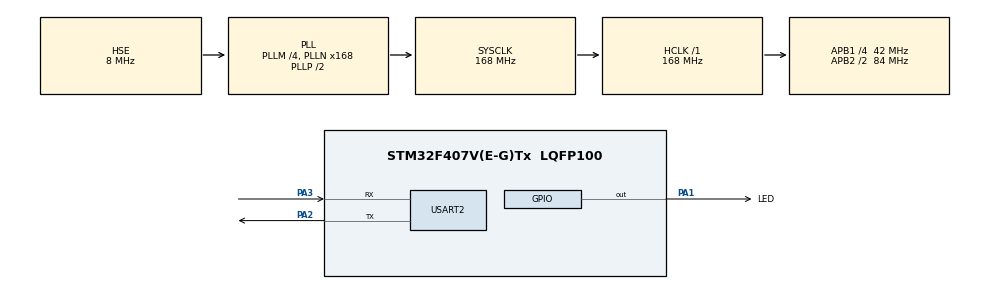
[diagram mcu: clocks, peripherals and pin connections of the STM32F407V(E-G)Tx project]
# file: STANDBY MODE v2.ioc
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Mcu.Family=STM32F4
Mcu.Name=STM32F407V(E-G)Tx
Mcu.Package=LQFP100
NVIC.PriorityGroup=NVIC_PRIORITYGROUP_4
NVIC.RTC_WKUP_IRQn=true\:0\:0\:false\:false\:true\:true\:true
PA0-WKUP.Mode=SYS_WakeUp0
PA0-WKUP.Signal=SYS_WKUP
PA1.GPIO_Label=LED
PA1.Signal=GPIO_Output
PA13.Mode=Serial_Wire
PA13.Signal=SYS_JTMS-SWDIO
PA14.Mode=Serial_Wire
PA14.Signal=SYS_JTCK-SWCLK
PA2.Mode=Asynchronous
PA2.Signal=USART2_TX
PA3.Mode=Asynchronous
PA3.Signal=USART2_RX
PH0-OSC_IN.Mode=HSE-External-Oscillator
PH0-OSC_IN.Signal=RCC_OSC_IN
PH1-OSC_OUT.Mode=HSE-External-Oscillator
PH1-OSC_OUT.Signal=RCC_OSC_OUT
ProjectManager.HeapSize=0x200
ProjectManager.StackSize=0x400
ProjectManager.TargetToolchain=STM32CubeIDE
RCC.48MHZClocksFreq_Value=84000000
RCC.AHBFreq_Value=168000000
RCC.APB1CLKDivider=RCC_HCLK_DIV4
RCC.APB1Freq_Value=42000000
RCC.APB1TimFreq_Value=84000000
RCC.APB2CLKDivider=RCC_HCLK_DIV2
RCC.APB2Freq_Value=84000000
RCC.APB2TimFreq_Value=168000000
RCC.CortexFreq_Value=168000000
RCC.HCLKFreq_Value=168000000
RCC.HSE_VALUE=8000000
RCC.HSI_VALUE=16000000
RCC.LSE_VALUE=32768
RCC.PLLM=4
RCC.PLLN=168
RCC.PLLSourceVirtual=RCC_PLLSOURCE_HSE
RCC.SYSCLKFreq_VALUE=168000000
RCC.SYSCLKSource=RCC_SYSCLKSOURCE_PLLCLK
RCC.VCOOutputFreq_Value=336000000
USART2.VirtualMode=VM_ASYNC
VP_RTC_VS_RTC_Activate.Mode=RTC_Enabled
VP_RTC_VS_RTC_WakeUp_intern.Mode=WakeUp
board=custom

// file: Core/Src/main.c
/* USER CODE BEGIN Header */
/**
  ******************************************************************************
  * @file           : main.c
  * @brief          : Main program body
  ******************************************************************************
  * @attention
  *
  * <h2><center>&copy; Copyright (c) 2021 STMicroelectronics.
  * All rights reserved.</center></h2>
  *
  * This software component is licensed by ST under BSD 3-Clause license,
  * the "License"; You may not use this file except in compliance with the
  * License. You may obtain a copy of the License at:
  *                        opensource.org/licenses/BSD-3-Clause
  *
  ******************************************************************************
  */
/* USER CODE END Header */
#include "main.h"

/* USER CODE BEGIN Includes */
#include "string.h"
/* USER CODE END Includes */

RTC_HandleTypeDef hrtc;

UART_HandleTypeDef huart2;

void SystemClock_Config(void);
static void MX_GPIO_Init(void);
static void MX_RTC_Init(void);
static void MX_USART2_UART_Init(void);

int main(void)
{

  /* MCU Configuration--------------------------------------------------------*/

  /* Reset of all peripherals, Initializes the Flash interface and the Systick. */
  HAL_Init();

  /* Configure the system clock */
  SystemClock_Config();

  /* Initialize all configured peripherals */
  MX_GPIO_Init();
  MX_RTC_Init();
  MX_USART2_UART_Init();
  /* USER CODE BEGIN 2 */

  /*** Check if the SB flag is set это означает, что MCU вышел из STANDBY MODE!***/
   if (__HAL_PWR_GET_FLAG(PWR_FLAG_SB) != RESET)
   {
 	  __HAL_PWR_CLEAR_FLAG(PWR_FLAG_SB);  // clear the flag

 	  /** display  the string **/
 	  char *str = "Wakeup from the STANDBY MODE\n\n";
 	  HAL_UART_Transmit(&huart2, (uint8_t *)str, strlen (str), HAL_MAX_DELAY);

 	  /** Blink the LED **/
 	  for (int i=0; i<20; i++)
 	  {
 		  HAL_GPIO_TogglePin(LED_GPIO_Port, LED_Pin);
 		  HAL_Delay(200);
 	  }

 	  /** Disable the WWAKEUP PIN **/
 	  HAL_PWR_DisableWakeUpPin(PWR_WAKEUP_PIN1);  // disable PA0

 	  /** Deactivate the RTC wakeup  **/
 	  HAL_RTCEx_DeactivateWakeUpTimer(&hrtc);
   }

   /** Now enter the standby mode **/
    /* Clear the WU FLAG */
   __HAL_PWR_CLEAR_FLAG(PWR_FLAG_WU);

    /* clear the RTC Wake UP (WU) flag */
   __HAL_RTC_WAKEUPTIMER_CLEAR_FLAG(&hrtc, RTC_FLAG_WUTF);

    /* Display the string */
   char *str = "About to enter the STANDBY MODE\n\n";
   HAL_UART_Transmit(&huart2, (uint8_t *)str, strlen (str), HAL_MAX_DELAY);

    /* Blink the LED */
   for (int i=0; i<5; i++)
   {
 	  HAL_GPIO_TogglePin(LED_GPIO_Port, LED_Pin);
 	  HAL_Delay(750);
   }

    /* Enable the WAKEUP PIN */
   HAL_PWR_EnableWakeUpPin(PWR_WAKEUP_PIN1); //Enable PA0

   /* enable the RTC Wakeup */
     /*  RTC Wake-up Interrupt Generation:
       Wake-up Time Base = (RTC_WAKEUPCLOCK_RTCCLK_DIV /(LSI))
       ==> WakeUpCounter = Wake-up Time / Wake-up Time Base

       To configure the wake up timer to 5s the WakeUpCounter is set to 0x2710:
       RTC_WAKEUPCLOCK_RTCCLK_DIV = RTCCLK_Div16 = 16
       Wake-up Time Base = 16 /(32KHz) = 0.0005 seconds
       ==> WakeUpCounter = ~5s/0.0005s = 10000 = 0x2710
       ==> WakeUpCounter = ~10s/0.0005s = 20000 = 0x4E20
       ==> WakeUpCounter = ~15s/0.0005s = 30000 = 0x7530
       ==> WakeUpCounter = ~60s/0.0005s = 120000 = 0x1D4C0
     */
   if (HAL_RTCEx_SetWakeUpTimer_IT(&hrtc, 0x1D4C0, RTC_WAKEUPCLOCK_RTCCLK_DIV16) != HAL_OK)
   {
     Error_Handler();
   }

    /* one last string to be sure */
   char *str2 = "STANDBY MODE is ON \n\n";
   HAL_UART_Transmit(&huart2, (uint8_t *)str2, strlen (str2), HAL_MAX_DELAY);

    /* Finally enter the standby mode */
   HAL_PWR_EnterSTANDBYMode();

  /* USER CODE END 2 */

  /* Infinite loop */
  while (1)
  {

  }
}

void SystemClock_Config(void)
{
  RCC_OscInitTypeDef RCC_OscInitStruct = {0};
  RCC_ClkInitTypeDef RCC_ClkInitStruct = {0};

  /** Configure the main internal regulator output voltage
  */
  __HAL_RCC_PWR_CLK_ENABLE();
  __HAL_PWR_VOLTAGESCALING_CONFIG(PWR_REGULATOR_VOLTAGE_SCALE1);
  /** Initializes the RCC Oscillators according to the specified parameters
  * in the RCC_OscInitTypeDef structure.
  */
  RCC_OscInitStruct.OscillatorType = RCC_OSCILLATORTYPE_LSI|RCC_OSCILLATORTYPE_HSE;
  RCC_OscInitStruct.HSEState = RCC_HSE_ON;
  RCC_OscInitStruct.LSIState = RCC_LSI_ON;
  RCC_OscInitStruct.PLL.PLLState = RCC_PLL_ON;
  RCC_OscInitStruct.PLL.PLLSource = RCC_PLLSOURCE_HSE;
  RCC_OscInitStruct.PLL.PLLM = 4;
  RCC_OscInitStruct.PLL.PLLN = 168;
  RCC_OscInitStruct.PLL.PLLP = RCC_PLLP_DIV2;
  RCC_OscInitStruct.PLL.PLLQ = 4;
  if (HAL_RCC_OscConfig(&RCC_OscInitStruct) != HAL_OK)
  {
    Error_Handler();
  }
  /** Initializes the CPU, AHB and APB buses clocks
  */
  RCC_ClkInitStruct.ClockType = RCC_CLOCKTYPE_HCLK|RCC_CLOCKTYPE_SYSCLK
                              |RCC_CLOCKTYPE_PCLK1|RCC_CLOCKTYPE_PCLK2;
  RCC_ClkInitStruct.SYSCLKSource = RCC_SYSCLKSOURCE_PLLCLK;
  RCC_ClkInitStruct.AHBCLKDivider = RCC_SYSCLK_DIV1;
  RCC_ClkInitStruct.APB1CLKDivider = RCC_HCLK_DIV4;
  RCC_ClkInitStruct.APB2CLKDivider = RCC_HCLK_DIV2;

  if (HAL_RCC_ClockConfig(&RCC_ClkInitStruct, FLASH_LATENCY_5) != HAL_OK)
  {
    Error_Handler();
  }
}

static void MX_RTC_Init(void)
{

  RTC_TimeTypeDef sTime = {0};
  RTC_DateTypeDef sDate = {0};

  /** Initialize RTC Only
  */
  hrtc.Instance = RTC;
  hrtc.Init.HourFormat = RTC_HOURFORMAT_24;
  hrtc.Init.AsynchPrediv = 127;
  hrtc.Init.SynchPrediv = 255;
  hrtc.Init.OutPut = RTC_OUTPUT_DISABLE;
  hrtc.Init.OutPutPolarity = RTC_OUTPUT_POLARITY_HIGH;
  hrtc.Init.OutPutType = RTC_OUTPUT_TYPE_OPENDRAIN;
  if (HAL_RTC_Init(&hrtc) != HAL_OK)
  {
    Error_Handler();
  }

  /** Initialize RTC and set the Time and Date
  */
  sTime.Hours = 0x0;
  sTime.Minutes = 0x0;
  sTime.Seconds = 0x0;
  sTime.DayLightSaving = RTC_DAYLIGHTSAVING_NONE;
  sTime.StoreOperation = RTC_STOREOPERATION_RESET;
  if (HAL_RTC_SetTime(&hrtc, &sTime, RTC_FORMAT_BCD) != HAL_OK)
  {
    Error_Handler();
  }
  sDate.WeekDay = RTC_WEEKDAY_MONDAY;
  sDate.Month = RTC_MONTH_JANUARY;
  sDate.Date = 0x1;
  sDate.Year = 0x0;

  if (HAL_RTC_SetDate(&hrtc, &sDate, RTC_FORMAT_BCD) != HAL_OK)
  {
    Error_Handler();
  }
  /** Enable the WakeUp
  */
 /* if (HAL_RTCEx_SetWakeUpTimer_IT(&hrtc, 0, RTC_WAKEUPCLOCK_RTCCLK_DIV16) != HAL_OK)
  {
    Error_Handler();
  }*/

}

static void MX_USART2_UART_Init(void)
{

  huart2.Instance = USART2;
  huart2.Init.BaudRate = 115200;
  huart2.Init.WordLength = UART_WORDLENGTH_8B;
  huart2.Init.StopBits = UART_STOPBITS_1;
  huart2.Init.Parity = UART_PARITY_NONE;
  huart2.Init.Mode = UART_MODE_TX_RX;
  huart2.Init.HwFlowCtl = UART_HWCONTROL_NONE;
  huart2.Init.OverSampling = UART_OVERSAMPLING_16;
  if (HAL_UART_Init(&huart2) != HAL_OK)
  {
    Error_Handler();
  }

}

static void MX_GPIO_Init(void)
{
  GPIO_InitTypeDef GPIO_InitStruct = {0};

  /* GPIO Ports Clock Enable */
  __HAL_RCC_GPIOH_CLK_ENABLE();
  __HAL_RCC_GPIOA_CLK_ENABLE();

  /*Configure GPIO pin Output Level */
  HAL_GPIO_WritePin(LED_GPIO_Port, LED_Pin, GPIO_PIN_RESET);

  /*Configure GPIO pin : LED_Pin */
  GPIO_InitStruct.Pin = LED_Pin;
  GPIO_InitStruct.Mode = GPIO_MODE_OUTPUT_PP;
  GPIO_InitStruct.Pull = GPIO_NOPULL;
  GPIO_InitStruct.Speed = GPIO_SPEED_FREQ_LOW;
  HAL_GPIO_Init(LED_GPIO_Port, &GPIO_InitStruct);

}

void Error_Handler(void)
{
  __disable_irq();
  while (1)
  {
  }
}

/************************ (C) COPYRIGHT STMicroelectronics *****END OF FILE****/
